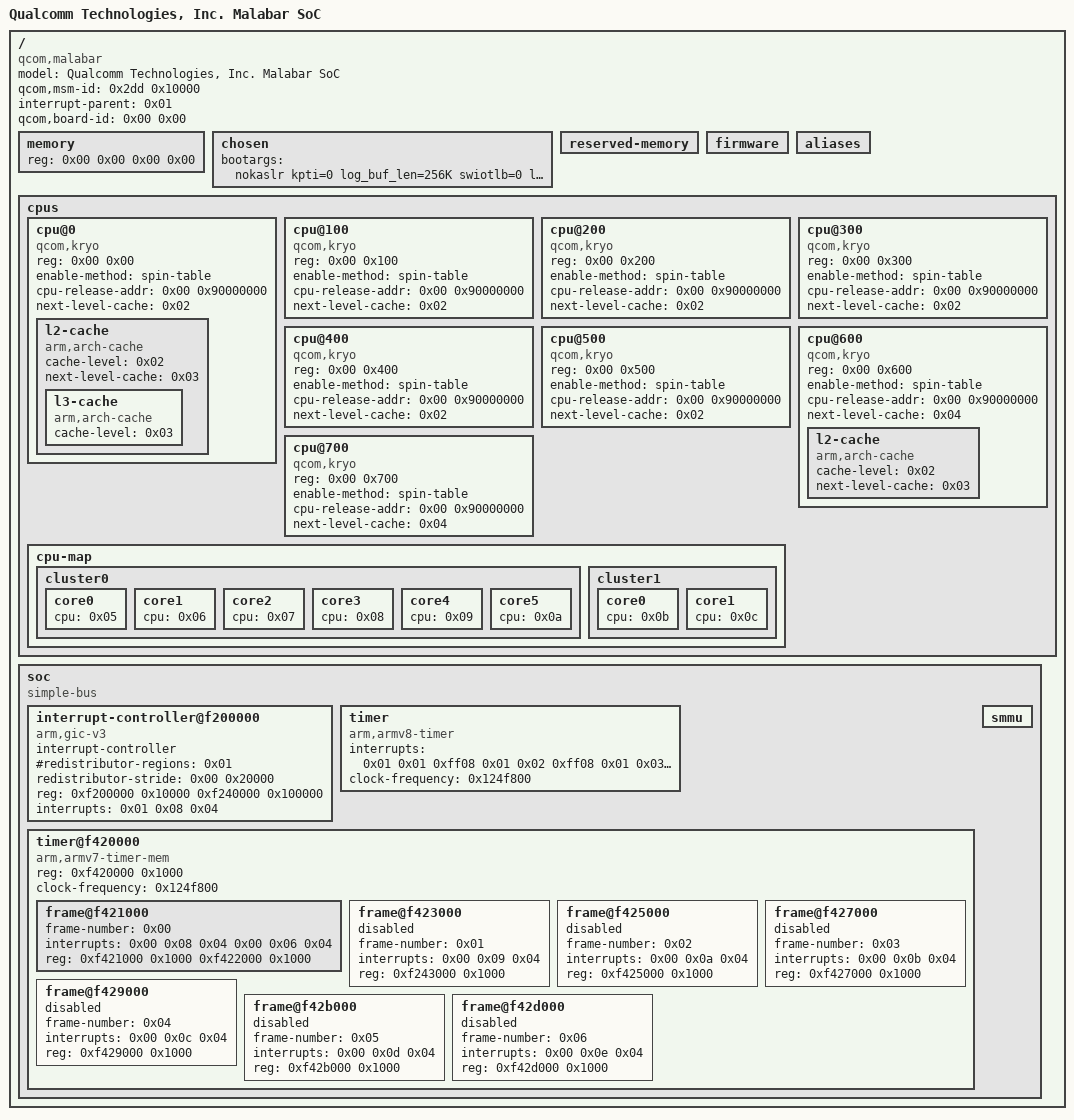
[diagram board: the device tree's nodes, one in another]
/dts-v1/;

/ {
	model = "Qualcomm Technologies, Inc. Malabar SoC";
	compatible = "qcom,malabar";
	qcom,msm-id = <0x2dd 0x10000>;
	interrupt-parent = <0x01>;
	#address-cells = <0x02>;
	#size-cells = <0x02>;
	qcom,board-id = <0x00 0x00>;

	memory {
		device_type = "memory";
		reg = <0x00 0x00 0x00 0x00>;
	};

	chosen {
		bootargs = "nokaslr kpti=0 log_buf_len=256K swiotlb=0 loop.max_part=7";
		phandle = <0x0d>;
	};

	reserved-memory {
		phandle = <0x0e>;
	};

	firmware {
		phandle = <0x0f>;
	};

	aliases {
	};

	cpus {
		#address-cells = <0x02>;
		#size-cells = <0x00>;

		cpu@0 {
			device_type = "cpu";
			compatible = "qcom,kryo";
			reg = <0x00 0x00>;
			enable-method = "spin-table";
			cpu-release-addr = <0x00 0x90000000>;
			next-level-cache = <0x02>;
			phandle = <0x05>;

			l2-cache {
				compatible = "arm,arch-cache";
				cache-level = <0x02>;
				next-level-cache = <0x03>;
				phandle = <0x02>;

				l3-cache {
					compatible = "arm,arch-cache";
					cache-level = <0x03>;
					phandle = <0x03>;
				};
			};
		};

		cpu@100 {
			device_type = "cpu";
			compatible = "qcom,kryo";
			reg = <0x00 0x100>;
			enable-method = "spin-table";
			cpu-release-addr = <0x00 0x90000000>;
			next-level-cache = <0x02>;
			phandle = <0x06>;
		};

		cpu@200 {
			device_type = "cpu";
			compatible = "qcom,kryo";
			reg = <0x00 0x200>;
			enable-method = "spin-table";
			cpu-release-addr = <0x00 0x90000000>;
			next-level-cache = <0x02>;
			phandle = <0x07>;
		};

		cpu@300 {
			device_type = "cpu";
			compatible = "qcom,kryo";
			reg = <0x00 0x300>;
			enable-method = "spin-table";
			cpu-release-addr = <0x00 0x90000000>;
			next-level-cache = <0x02>;
			phandle = <0x08>;
		};

		cpu@400 {
			device_type = "cpu";
			compatible = "qcom,kryo";
			reg = <0x00 0x400>;
			enable-method = "spin-table";
			cpu-release-addr = <0x00 0x90000000>;
			next-level-cache = <0x02>;
			phandle = <0x09>;
		};

		cpu@500 {
			device_type = "cpu";
			compatible = "qcom,kryo";
			reg = <0x00 0x500>;
			enable-method = "spin-table";
			cpu-release-addr = <0x00 0x90000000>;
			next-level-cache = <0x02>;
			phandle = <0x0a>;
		};

		cpu@600 {
			device_type = "cpu";
			compatible = "qcom,kryo";
			reg = <0x00 0x600>;
			enable-method = "spin-table";
			cpu-release-addr = <0x00 0x90000000>;
			next-level-cache = <0x04>;
			phandle = <0x0b>;

			l2-cache {
				compatible = "arm,arch-cache";
				cache-level = <0x02>;
				next-level-cache = <0x03>;
				phandle = <0x04>;
			};
		};

		cpu@700 {
			device_type = "cpu";
			compatible = "qcom,kryo";
			reg = <0x00 0x700>;
			enable-method = "spin-table";
			cpu-release-addr = <0x00 0x90000000>;
			next-level-cache = <0x04>;
			phandle = <0x0c>;
		};

		cpu-map {

			cluster0 {

				core0 {
					cpu = <0x05>;
				};

				core1 {
					cpu = <0x06>;
				};

				core2 {
					cpu = <0x07>;
				};

				core3 {
					cpu = <0x08>;
				};

				core4 {
					cpu = <0x09>;
				};

				core5 {
					cpu = <0x0a>;
				};
			};

			cluster1 {

				core0 {
					cpu = <0x0b>;
				};

				core1 {
					cpu = <0x0c>;
				};
			};
		};
	};

	soc {
		#address-cells = <0x01>;
		#size-cells = <0x01>;
		ranges = <0x00 0x00 0x00 0xffffffff>;
		compatible = "simple-bus";
		phandle = <0x10>;

		interrupt-controller@f200000 {
			compatible = "arm,gic-v3";
			#interrupt-cells = <0x03>;
			interrupt-controller;
			#redistributor-regions = <0x01>;
			redistributor-stride = <0x00 0x20000>;
			reg = <0xf200000 0x10000 0xf240000 0x100000>;
			interrupts = <0x01 0x08 0x04>;
			phandle = <0x01>;
		};

		timer {
			compatible = "arm,armv8-timer";
			interrupts = <0x01 0x01 0xff08 0x01 0x02 0xff08 0x01 0x03 0xff08 0x01 0x00 0xff08>;
			clock-frequency = <0x124f800>;
			phandle = <0x11>;
		};

		timer@f420000 {
			#address-cells = <0x01>;
			#size-cells = <0x01>;
			ranges;
			compatible = "arm,armv7-timer-mem";
			reg = <0xf420000 0x1000>;
			clock-frequency = <0x124f800>;
			phandle = <0x12>;

			frame@f421000 {
				frame-number = <0x00>;
				interrupts = <0x00 0x08 0x04 0x00 0x06 0x04>;
				reg = <0xf421000 0x1000 0xf422000 0x1000>;
			};

			frame@f423000 {
				frame-number = <0x01>;
				interrupts = <0x00 0x09 0x04>;
				reg = <0xf243000 0x1000>;
				status = "disabled";
			};

			frame@f425000 {
				frame-number = <0x02>;
				interrupts = <0x00 0x0a 0x04>;
				reg = <0xf425000 0x1000>;
				status = "disabled";
			};

			frame@f427000 {
				frame-number = <0x03>;
				interrupts = <0x00 0x0b 0x04>;
				reg = <0xf427000 0x1000>;
				status = "disabled";
			};

			frame@f429000 {
				frame-number = <0x04>;
				interrupts = <0x00 0x0c 0x04>;
				reg = <0xf429000 0x1000>;
				status = "disabled";
			};

			frame@f42b000 {
				frame-number = <0x05>;
				interrupts = <0x00 0x0d 0x04>;
				reg = <0xf42b000 0x1000>;
				status = "disabled";
			};

			frame@f42d000 {
				frame-number = <0x06>;
				interrupts = <0x00 0x0e 0x04>;
				reg = <0xf42d000 0x1000>;
				status = "disabled";
			};
		};

		smmu {
			phandle = <0x13>;
		};
	};

	__symbols__ {
		chosen = "/chosen";
		reserved_memory = "/reserved-memory";
		firmware = "/firmware";
		CPU0 = "/cpus/cpu@0";
		L2_0 = "/cpus/cpu@0/l2-cache";
		L3_0 = "/cpus/cpu@0/l2-cache/l3-cache";
		CPU1 = "/cpus/cpu@100";
		CPU2 = "/cpus/cpu@200";
		CPU3 = "/cpus/cpu@300";
		CPU4 = "/cpus/cpu@400";
		CPU5 = "/cpus/cpu@500";
		CPU6 = "/cpus/cpu@600";
		L2_6 = "/cpus/cpu@600/l2-cache";
		CPU7 = "/cpus/cpu@700";
		soc = "/soc";
		intc = "/soc/interrupt-controller@f200000";
		arch_timer = "/soc/timer";
		memtimer = "/soc/timer@f420000";
		apps_smmu = "/soc/smmu";
	};
};
